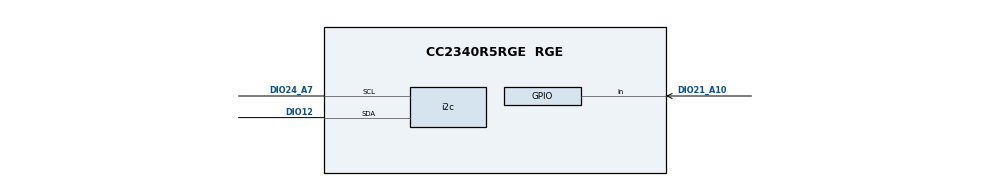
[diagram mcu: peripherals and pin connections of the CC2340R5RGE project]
// @cliArgs --device "CC2340R5RGE" --package "RGE" --rtos "freertos"

/*
 *  pwrtest.syscfg - BSN-C23-A static current test (no BLE stack, no UART)
 *
 *  Pin map: see ../common/bsn_board.h
 */

/* ======== Kernel ======== */
const FreeRTOS = scripting.addModule("/freertos/FreeRTOS");
FreeRTOS.heapSize = 0x2000;
scripting.addModule("/ti/posix/freertos/Settings");

/* ======== Board ======== */
// Without a --board, the generated Board_init() still bit-bangs a LaunchPad SPI-flash
// shutdown sequence on DIO11/13/21/24, which are UART TX, HDC INT and I2C SCL here.
const Board = scripting.addModule("/ti/drivers/Board");
Board.generateInitializationFunctions = false;

/* ======== Device configuration (CCFG) ======== */
const CCFG = scripting.addModule("/ti/devices/CCFG");
// X2 (32.768 kHz crystal) is not fitted on rev A, so use the internal RC oscillator.
CCFG.srcClkLF = "LF RCOSC";
// Same HFXT trim as ble_sensor and cwtest, so the clock setup matches the real firmware.
CCFG.overrideHfxtCapArray = true;
CCFG.hfxtCapArrayQ1 = 44;
CCFG.hfxtCapArrayQ2 = 44;
// The ROM serial bootloader is disabled once this image is flashed (SDK default);
// recover over SWD with "make erase". Never enable its pin trigger: the default
// trigger pin DIO21 is the HDC2010 INT line.

/* ======== I2C (HDC2010) ======== */
const I2C = scripting.addModule("/ti/drivers/I2C", {}, false);
const i2c = I2C.addInstance();
i2c.$name = "CONFIG_I2C_SENSOR";
i2c.i2c.sdaPin.$assign = "DIO12";
i2c.i2c.sclPin.$assign = "DIO24_A7";

/* ======== GPIO ======== */
const GPIO = scripting.addModule("/ti/drivers/GPIO");
// HDC2010 DRDY/INT. The pin is high-Z until the sensor is configured, so a pull-down
// keeps it from floating.
const hdcInt = GPIO.addInstance();
hdcInt.$name = "CONFIG_GPIO_HDC_INT";
hdcInt.mode = "Input";
hdcInt.pull = "Pull Down";
// No interrupt trigger here: MODE=sensor_irq sets the rising edge at runtime, so the
// static modes keep the pin configuration they were first measured with.
hdcInt.gpioPin.$assign = "DIO21_A10";

/* ======== Other drivers ======== */
scripting.addModule("/ti/drivers/Power");
scripting.addModule("/ti/drivers/BatteryMonitor");
